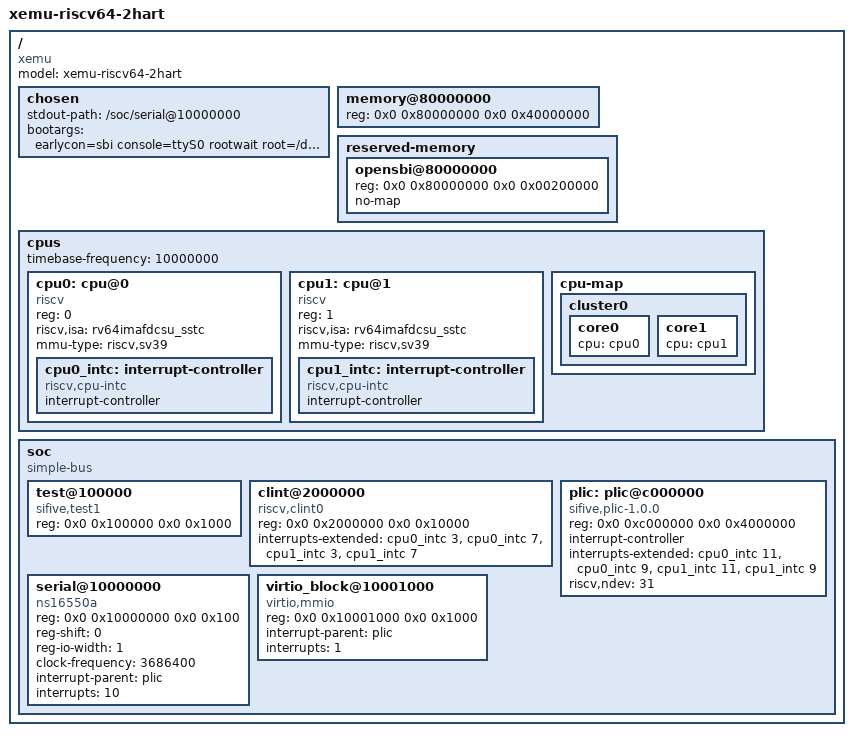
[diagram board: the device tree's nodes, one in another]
/dts-v1/;

/ {
	#address-cells = <2>;
	#size-cells = <2>;
	compatible = "xemu";
	model = "xemu-riscv64-2hart";

	chosen {
		stdout-path = "/soc/serial@10000000";
		bootargs = "earlycon=sbi console=ttyS0 rootwait root=/dev/vda rw";
	};

	memory@80000000 {
		device_type = "memory";
		reg = <0x0 0x80000000 0x0 0x40000000>;
	};

	reserved-memory {
		#address-cells = <2>;
		#size-cells = <2>;
		ranges;

		opensbi@80000000 {
			reg = <0x0 0x80000000 0x0 0x00200000>;
			no-map;
		};
	};

	cpus {
		#address-cells = <1>;
		#size-cells = <0>;
		timebase-frequency = <10000000>;

		cpu0: cpu@0 {
			device_type = "cpu";
			reg = <0>;
			status = "okay";
			compatible = "riscv";
			riscv,isa = "rv64imafdcsu_sstc";
			mmu-type = "riscv,sv39";

			cpu0_intc: interrupt-controller {
				#interrupt-cells = <1>;
				interrupt-controller;
				compatible = "riscv,cpu-intc";
			};
		};

		cpu1: cpu@1 {
			device_type = "cpu";
			reg = <1>;
			status = "okay";
			compatible = "riscv";
			riscv,isa = "rv64imafdcsu_sstc";
			mmu-type = "riscv,sv39";

			cpu1_intc: interrupt-controller {
				#interrupt-cells = <1>;
				interrupt-controller;
				compatible = "riscv,cpu-intc";
			};
		};

		cpu-map {
			cluster0 {
				core0 { cpu = <&cpu0>; };
				core1 { cpu = <&cpu1>; };
			};
		};
	};

	soc {
		#address-cells = <2>;
		#size-cells = <2>;
		compatible = "simple-bus";
		ranges;

		test@100000 {
			compatible = "sifive,test1", "sifive,test0", "syscon";
			reg = <0x0 0x100000 0x0 0x1000>;
		};

		clint@2000000 {
			compatible = "riscv,clint0";
			reg = <0x0 0x2000000 0x0 0x10000>;
			interrupts-extended = <&cpu0_intc 3>, <&cpu0_intc 7>,
			                      <&cpu1_intc 3>, <&cpu1_intc 7>;
		};

		plic: plic@c000000 {
			compatible = "sifive,plic-1.0.0", "riscv,plic0";
			reg = <0x0 0xc000000 0x0 0x4000000>;
			#interrupt-cells = <1>;
			interrupt-controller;
			interrupts-extended = <&cpu0_intc 11>, <&cpu0_intc 9>,
			                      <&cpu1_intc 11>, <&cpu1_intc 9>;
			riscv,ndev = <31>;
		};

		serial@10000000 {
			compatible = "ns16550a";
			reg = <0x0 0x10000000 0x0 0x100>;
			reg-shift = <0>;
			reg-io-width = <1>;
			clock-frequency = <3686400>;
			interrupt-parent = <&plic>;
			interrupts = <10>;
		};

		virtio_block@10001000 {
			compatible = "virtio,mmio";
			reg = <0x0 0x10001000 0x0 0x1000>;
			interrupt-parent = <&plic>;
			interrupts = <1>;
		};
	};
};
